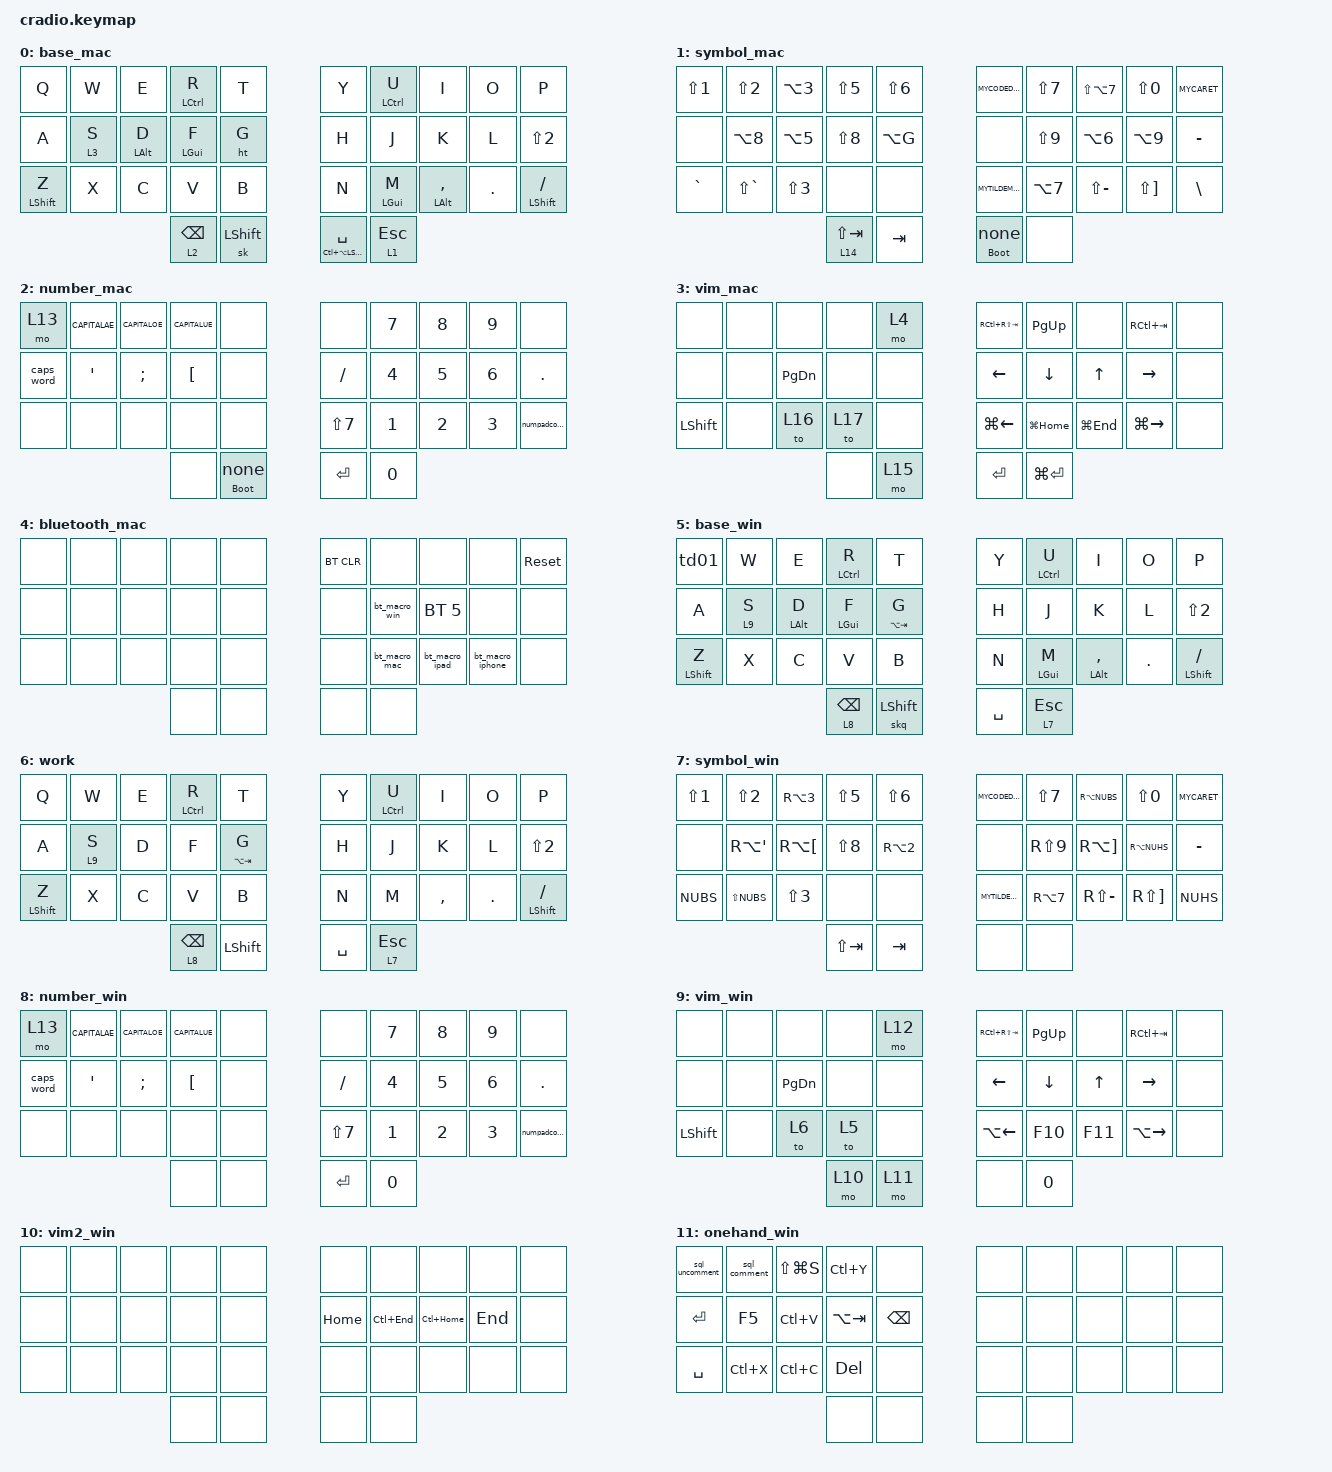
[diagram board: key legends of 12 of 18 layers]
// Copyright (c) 2022 The ZMK Contributors
// SPDX-License-Identifier: MIT

#include <behaviors.dtsi>
#include <dt-bindings/zmk/keys.h>
#include <dt-bindings/zmk/bt.h>

&sl {
    release-after-ms = <500>;
};

/ {
    behaviors {
        ht: hold_tap {
            label = "hold_tap";
            compatible = "zmk,behavior-hold-tap";
            #binding-cells = <2>;
            flavor = "balanced";
            tapping-term-ms = <150>;
            quick-tap-ms = <70>;
            global-quick-tap;
            bindings = <&kp>, <&kp>;
        };
        cht: custom_hold_tap {
            compatible = "zmk,behavior-hold-tap";
            label = "nested_ht_with_sk";
            #binding-cells = <2>;
            tapping-term-ms = <500>;
            flavor = "tap-preferred";
            bindings = <&mo>, <&skq>;
        };
        ht_reset: hold_tap_reset {
            label = "hold_tap_reset";
            compatible = "zmk,behavior-hold-tap";
            #binding-cells = <2>;
            flavor = "tap-preferred";
            tapping-term-ms = <3000>;
            quick-tap-ms = <150>;
            bindings = <&bootloader>, <&none>;
        };
      skq: sticky_key_quick_release {
           compatible = "zmk,behavior-sticky-key";
           label = "STICKY_KEY_QUICK_RELEASE";
           #binding-cells = <1>;
           bindings = <&kp>;
           release-after-ms = <700>;
           quick-release;
        };
// global quick tap to improve home row mod behavior ior when typing fast
      gqt: global-quick-tap {
           compatible = "zmk,behavior-hold-tap";
           label = "GLOBAL_QUICK_TAP";
           #binding-cells = <2>;
           flavor = "tap-preferred";
           tapping-term-ms = <200>;
           quick-tap-ms = <125>;
           global-quick-tap;
           bindings = <&kp>, <&kp>;
        };
//custom hold tap for layer tap - lqt
      lqt: layer-quick-tap {
           compatible = "zmk,behavior-hold-tap";
           label = "LAYER_QUICK_TAP";
           #binding-cells = <2>;
           flavor = "hold-preferred";
           tapping-term-ms = <200>;
           quick-tap-ms = <125>;
           bindings = <&mo>, <&kp>;
        };
// archived tapdances
//      lqt_td: layer-quick-tap-tap-dance {
//           compatible = "zmk,behavior-hold-tap";
//           label = "LAYER_QUICK_TAP_TAP_DANCE";
//           #binding-cells = <2>;
//           flavor = "hold-preferred";
//           tapping-term-ms = <125>;
//           quick-tap-ms = <50>;
//           bindings = <&mo>, <&td1>;
//        };
//      lqt_td2: layer-quick-tap-tap-dance2 {
//           compatible = "zmk,behavior-hold-tap";
//           label = "LAYER_QUICK_TAP_TAP_DANCE2";
//           #binding-cells = <2>;
//           flavor = "hold-preferred";
//           tapping-term-ms = <200>;
//           quick-tap-ms = <225>;
//           bindings = <&mo>, <&td2>;
//        };
//      td1: td1 {
//           compatible = "zmk,behavior-tap-dance";
//           label = "td_left_thumb_1";
//           #binding-cells = <0>;
//           tapping-term-ms = <40>; //max time between taps
//           bindings =
//           <&kp BSPC>, <&kp LA(BSPC)>;
//          };
    // tap_dance to have tab dance and q
      td01: td01 {
           compatible = "zmk,behavior-tap-dance";
           #binding-cells = <0>;
           tapping-term-ms = <150>;
           bindings =
           <&kp Q>, <&macro_alttab>;
          };
    };

//    combos {
//        compatible = "zmk,combos";
//        combo_esc {
//            timeout-ms = <50>;
//            key-positions = <0 1>;
//            bindings = <&kp LG(SPACE)>;
//           };
//    };

//    conditional_layers {
//        compatible = "zmk,conditional-layers";
//        bt_layer {
//            if-layers = <1 2>;
//            then-layer = <3>;
//        };
//    };

    macros {
        sql_comment: sql_comment {
            label = "sql_comment";
            compatible = "zmk,behavior-macro";
            #binding-cells = <0>;
            bindings
                = <&macro_press &kp LCTRL>
                , <&macro_tap &kp K>
                , <&macro_tap &kp C>
                , <&macro_release &kp LCTRL>
                , <&macro_tap &kp RIGHT>
                ;
        };
        sql_uncomment: sql_uncomment {
            label = "sql_uncomment";
            compatible = "zmk,behavior-macro";
            #binding-cells = <0>;
            bindings
                = <&macro_press &kp LCTRL>
                , <&macro_tap &kp K>
                , <&macro_tap &kp U>
                , <&macro_release &kp LCTRL>
                , <&macro_tap &kp RIGHT>
                ;
        };
        numpadcomma: numpadcomma {
            label = "numpadcomma";
            compatible = "zmk,behavior-macro";
            #binding-cells = <0>;
            bindings
                = <&macro_tap &kp COMMA>
                , <&macro_tap &kp SPACE>
                ;
        };
        CAPITALAE: CAPITALAE {
            label = "CAPITALAE";
            compatible = "zmk,behavior-macro";
            #binding-cells = <0>;
            bindings
                = <&macro_tap &kp CAPS>
                , <&macro_tap &kp SQT>
                , <&macro_tap &kp CAPS>
                ;
        };
        CAPITALOE: CAPITALOE {
            label = "CAPITALOE";
            compatible = "zmk,behavior-macro";
            #binding-cells = <0>;
            bindings
                = <&macro_tap &kp CAPS>
                , <&macro_tap &kp SEMI>
                , <&macro_tap &kp CAPS>
                ;
        };
        CAPITALUE: CAPITALUE {
            label = "CAPITALUE";
            compatible = "zmk,behavior-macro";
            #binding-cells = <0>;
            bindings
                = <&macro_tap &kp CAPS>
                , <&macro_tap &kp LBKT>
                , <&macro_tap &kp CAPS>
                ;
        };
        MYCARET: MYCARET {
            label = "MYCARET";
            compatible = "zmk,behavior-macro";
            #binding-cells = <0>;
            bindings
                = <&macro_tap &kp EQUAL>
                , <&macro_tap &kp SPACE>
                ;
        };
        MYTILDEMAC: MYTILDEMAC {
            label = "MYTILDEMAC";
            compatible = "zmk,behavior-macro";
            #binding-cells = <0>;
            bindings
                = <&macro_press &kp LALT>
                , <&macro_tap &kp N>
                , <&macro_release &kp LALT>
                , <&macro_tap &kp SPACE>
                ;
        };
        MYTILDEWIN: MYTILDEWIN {
            label = "MYTILDEWIN";
            compatible = "zmk,behavior-macro";
            #binding-cells = <0>;
            bindings
                = <&macro_press &kp RALT>
                , <&macro_tap &kp EQUAL>
                , <&macro_release &kp RALT>
                , <&macro_tap &kp SPACE>
                ;
        };
        MYCODEDELIM:  MYCODEDELIM {
            label = "MYCODEDELIM";
            compatible = "zmk,behavior-macro";
            #binding-cells = <0>;
            bindings
                = <&macro_tap &kp RS(EQUAL)>
                , <&macro_tap &kp SPACE>
                ;
        };
        bt_macro_mac: bt_macro_mac {
            label = "bt_macro_mac";
            compatible = "zmk,behavior-macro";
            #binding-cells = <0>;
            wait-ms = <0>;
            tap-ms = <0>;
            bindings = <&to 0>,  <&bt BT_SEL 1>;
        };
        bt_macro_win: bt_macro_win {
            label = "bt_macro_win";
            compatible = "zmk,behavior-macro";
            #binding-cells = <0>;
            wait-ms = <0>;
            tap-ms = <0>;
            bindings = <&to 5>,  <&bt BT_SEL 4>;
        };
        bt_macro_iphone: bt_macro_iphone {
            label = "bt_macro_iphone";
            compatible = "zmk,behavior-macro";
            #binding-cells = <0>;
            wait-ms = <0>;
            tap-ms = <0>;
            bindings = <&to 0>,  <&bt BT_SEL 3>;
        };
        bt_macro_ipad: bt_macro_ipad {
            label = "bt_macro_ipad";
            compatible = "zmk,behavior-macro";
            #binding-cells = <0>;
            wait-ms = <0>;
            tap-ms = <0>;
            bindings = <&to 0>,  <&bt BT_SEL 2>;
        };
        macro_alttab: macro_alttab {
            compatible = "zmk,behavior-macro";
            #binding-cells = <0>;
            bindings
                = <&macro_press &kp LALT>
                , <&macro_tap &kp TAB>
                , <&macro_pause_for_release>
                , <&macro_release &kp TAB>
                ;
        };
        app_switch: app_switch {
            compatible = "zmk,behavior-macro";
            #binding-cells = <0>;
            bindings
                = <&macro_press &kp LGUI>
                , <&macro_tap &kp TAB>
                , <&macro_pause_for_release>
                , <&macro_release &kp LGUI>;
        };
    };

// layernames will have the ending digit 1 if they are intended for use with MACOS
// layernames will have the ending digit 2 if they are intended for use with WINDOWS


    keymap {
        compatible = "zmk,keymap";

        // LAYER 0 base_mac
        base_mac {
            bindings = <
        //╭──────────┬──────────┬──────────┬──────────┬──────────╮   ╭──────────┬──────────┬──────────┬──────────┬──────────╮
        //│  Q       │  W       │  E       │  R       │  T       │   │  Z       │  U       │  I       │  O       │  P       │
            &kp Q      &kp W      &kp E     &ht LCTRL R &kp T          &kp Y    &ht LCTRL U   &kp I      &kp O      &kp P
        //├──────────┼──────────┼──────────┼──────────┼──────────┤   ├──────────┼──────────┼──────────┼──────────┼──────────┤
        //│  A       │  S       │  D       │  F       │  G       │   │  H       │  J       │  K       │  L       │  "       │
            &kp A      &lt 3 S    &ht LALT D   &ht LGUI F  &ht G      &kp H     &kp J       &kp K     &kp L     &kp LS(N2)
        //├──────────┼──────────┼──────────┼──────────┼──────────┤   ├──────────┼──────────┼──────────┼──────────┼──────────┤
        //│  Y       │  X       │  C       │  V       │  B       │   │  N       │  M       │ , <      │ . >      │ / ?      │
           &ht LSHIFT Z &kp X      &kp  C     &kp V      &kp B          &kp N     &ht LGUI M  &ht LALT COMMA &kp DOT &ht LSHIFT FSLH
        //╰──────────┴──────────┴──────────┼──────────┼──────────┤   ├──────────┼──────────┼──────────┴──────────┴──────────╯
                                            &lqt 2 BSPC &sk LSHIFT     &ht LC(LA(LSHIFT)) SPACE  &lqt 1 ESCAPE
        //                                 ╰──────────┴──────────╯   ╰──────────┴──────────╯
            >;
        };

// LAYER 1 symbol_mac
        symbol_mac {
            bindings = <
        //╭──────────┬──────────┬──────────┬──────────┬──────────╮   ╭──────────┬──────────┬──────────┬──────────┬──────────╮
        //│ +        │  "       │ \#       │  %       │    &     │   │   \`     │   /      │   \      │   =      │ caret    │
            &kp LS(N1) &kp LS(N2) &kp LA(N3) &kp LS(N5)  &kp LS(N6)    &MYCODEDELIM  &kp LS(N7)  &kp LS(LA(N7)) &kp LS(N0) &MYCARET
        //├──────────┼──────────┼──────────┼──────────┼──────────┤   ├──────────┼──────────┼──────────┼──────────┼──────────┤
        //│          │  {       │  [       │  (       │          │   │          │    )     │  ]       │     }    │  '       │
           &none   &kp LA(N8) &kp LA(N5) &kp LS(N8) &kp LA(G)        &none  &kp LS(N9) &kp LA(N6) &kp LA(N9) &kp MINUS
        //├──────────┼──────────┼──────────┼──────────┼──────────┤   ├──────────┼──────────┼──────────┼──────────┼──────────┤
        //│ <        │  >       │  *       │  9       │          │   │ tilde    │  pipe    │  ?       │     !    │  $       │
           &kp GRAVE   &kp LS(GRAVE) &kp LS(N3) &none    &none      &MYTILDEMAC    &kp LA(N7)   &kp LS(MINUS) &kp LS(RBKT) &kp BSLH
        //╰──────────┴──────────┴──────────┼──────────┼──────────┤   ├──────────┼──────────┼──────────┴──────────┴──────────╯
                                             &lt 14 LS(TAB) &kp TAB   &ht_reset 0 0  &none
        //                                 ╰──────────┴──────────╯   ╰──────────┴──────────╯
            >;
        };

// LAYER 2 number_mac
        number_mac {
            bindings = <
        //╭──────────┬──────────┬──────────┬──────────┬──────────╮   ╭──────────┬──────────┬──────────┬──────────┬──────────╮
        //│          │          │          │          │          │   │          │  7       │  8       │  9       │          │
            &mo 13      &CAPITALAE     &CAPITALOE      &CAPITALUE      &none          &none      &kp N7     &kp N8     &kp N9   &none
        //├──────────┼──────────┼──────────┼──────────┼──────────┤   ├──────────┼──────────┼──────────┼──────────┼──────────┤
        //│          │ ä        │   ö      │   ü      │          │   │     -    │  4       │  5       │  6       │          │
           &caps_word      &kp SQT     &kp SEMI     &kp LBKT  &none    &kp FSLH &kp N4     &kp N5     &kp N6     &kp DOT
        //├──────────┼──────────┼──────────┼──────────┼──────────┤   ├──────────┼──────────┼──────────┼──────────┼──────────┤
        //│          │          │          │          │          │   │     /    │  1       │   2      │    3     │          │
            &none      &none      &none      &none       &none         &kp LS(N7)     &kp N1    &kp N2     &kp N3     &numpadcomma
        //╰──────────┴──────────┴──────────┼──────────┼──────────┤   ├──────────┼──────────┼──────────┴──────────┴──────────╯
                                             &none  &ht_reset 0 0  &kp ENTER   &kp N0
        //                                 ╰──────────┴──────────╯   ╰──────────┴──────────╯
            >;
        };

// LAYER 3 vim_mac
        vim_mac {
            bindings = <
        //╭──────────┬──────────┬──────────┬──────────┬──────────╮   ╭──────────┬──────────┬──────────┬──────────┬──────────╮
        //│          │          │          │          │          │   │          │          │          │          │          │
            &none      &none     &none      &none      &mo 4           &kp RC(RS(TAB))      &kp PG_UP     &none   &kp RC(TAB)   &none
        //├──────────┼──────────┼──────────┼──────────┼──────────┤   ├──────────┼──────────┼──────────┼──────────┼──────────┤
        //│          │          │          │          │          │   │          │          │          │          │          │
           &none      &none      &kp PG_DN     &none       &none         &kp LEFT    &kp DOWN   &kp UP    &kp RIGHT  &none
        //├──────────┼──────────┼──────────┼──────────┼──────────┤   ├──────────┼──────────┼──────────┼──────────┼──────────┤
        //│          │          │          │          │          │   │          │          │          │          │          │
            &kp LSHIFT   &none     &to 16     &to 17      &none       &kp LG(LEFT) &kp LG(HOME) &kp LG(END) &kp LG(RIGHT)  &none
        //╰──────────┴──────────┴──────────┼──────────┼──────────┤   ├──────────┼──────────┼──────────┴──────────┴──────────╯
                                             &none      &mo 15          &kp ENTER      &kp LG(ENTER)
        //                                 ╰──────────┴──────────╯   ╰──────────┴──────────╯
            >;
        };

// LAYER 4 bluetooth_mac
        bluetooth_mac {
            bindings = <
        //╭──────────┬──────────┬──────────┬──────────┬──────────╮   ╭──────────┬──────────┬──────────┬──────────┬──────────╮
        //│          │          │          │          │          │   │ CLEAR BT │          │          │          │          │
            &none     &none      &none      &none     &none          &bt BT_CLR &none      &none      &none       &sys_reset
        //├──────────┼──────────┼──────────┼──────────┼──────────┤   ├──────────┼──────────┼──────────┼──────────┼──────────┤
        //│          │          │          │          │          │   │          │Profile 4 │Profile 5 │          │          │
          &none  &none      &none      &none     &none           &none   &bt_macro_win &bt BT_SEL 5 &none     &none
        //├──────────┼──────────┼──────────┼──────────┼──────────┤   ├──────────┼──────────┼──────────┼──────────┼──────────┤
        //│          │          │          │          │          │   │          │Profile 1 │Profile 2 │Profile 3 │          │
            &none      &none      &none     &none        &none         &none     &bt_macro_mac &bt_macro_ipad &bt_macro_iphone &none
        //╰──────────┴──────────┴──────────┼──────────┼──────────┤   ├──────────┼──────────┼──────────┴──────────┴──────────╯
                                             &none      &none          &none      &none
        //                                 ╰──────────┴──────────╯   ╰──────────┴──────────╯
            >;
        };

//// LAYER 4 bluetooth_layer1 (uncommented no macros)
//        bluetooth_layer1 {
//            bindings = <
//        //╭──────────┬──────────┬──────────┬──────────┬──────────╮   ╭──────────┬──────────┬──────────┬──────────┬──────────╮
//        //│          │          │          │          │          │   │ CLEAR BT │          │          │          │          │
//            &none     &none      &none      &none     &none          &bt BT_CLR &none      &none      &none       &sys_reset
//        //├──────────┼──────────┼──────────┼──────────┼──────────┤   ├──────────┼──────────┼──────────┼──────────┼──────────┤
//        //│          │          │          │          │          │   │          │Profile 4 │Profile 5 │          │          │
//          &none  &none      &none      &none     &none           &none   &bt BT_SEL 4 &bt BT_SEL 5 &none     &none
//        //├──────────┼──────────┼──────────┼──────────┼──────────┤   ├──────────┼──────────┼──────────┼──────────┼──────────┤
//        //│          │          │          │          │          │   │          │Profile 1 │Profile 2 │Profile 3 │          │
//            &none      &none      &none     &none        &none         &none     &bt BT_SEL 1 &bt BT_SEL 2 &bt BT_SEL 3 &none
//        //╰──────────┴──────────┴──────────┼──────────┼──────────┤   ├──────────┼──────────┼──────────┴──────────┴──────────╯
//                                             &none      &none          &to 0      &to 5
//        //                                 ╰──────────┴──────────╯   ╰──────────┴──────────╯
//            >;
//        };

// LAYER 5 base_win
        base_win {
            bindings = <
        //╭──────────┬──────────┬──────────┬──────────┬──────────╮   ╭──────────┬──────────┬──────────┬──────────┬──────────╮
        //│  Q       │  W       │  E       │  R       │  T       │   │  Z       │  U       │  I       │  O       │  P       │
            &td01      &kp W      &kp E     &ht LCTRL R &kp T          &kp Y      &ht LCTRL U      &kp I      &kp O      &kp P
        //├──────────┼──────────┼──────────┼──────────┼──────────┤   ├──────────┼──────────┼──────────┼──────────┼──────────┤
        //│  A       │  S       │  D       │  F       │  G       │   │  H       │  J       │  K       │  L       │  "      │
            &kp A      &lt 9 S    &ht LALT D  &ht LGUI F    &ht LA(TAB) G   &kp H      &kp J       &kp K     &kp L      &kp LS(N2)
        //├──────────┼──────────┼──────────┼──────────┼──────────┤   ├──────────┼──────────┼──────────┼──────────┼──────────┤
        //│  Y       │  X       │  C       │  V       │  B       │   │  N       │  M       │ , <      │ . >      │ / ?      │
           &ht LSHIFT Z &kp X      &kp  C     &kp V     &kp B          &kp N     &ht LGUI M  &ht LALT COMMA &kp DOT &ht LSHIFT FSLH
        //╰──────────┴──────────┴──────────┼──────────┼──────────┤   ├──────────┼──────────┼──────────┴──────────┴──────────╯
                                            &lqt 8 BSPC &skq LSHIFT     &kp SPACE  &lqt 7 ESCAPE
        //                                 ╰──────────┴──────────╯   ╰──────────┴──────────╯
            >;
        };

// LAYER 6 work - not sure whether needed
        work {
            bindings = <
        //╭──────────┬──────────┬──────────┬──────────┬──────────╮   ╭──────────┬──────────┬──────────┬──────────┬──────────╮
        //│  Q       │  W       │  E       │  R       │  T       │   │  Z       │  U       │  I       │  O       │  P       │
            &kp Q      &kp W      &kp E     &ht LCTRL R &kp T          &kp Y      &ht LCTRL U      &kp I      &kp O      &kp P
        //├──────────┼──────────┼──────────┼──────────┼──────────┤   ├──────────┼──────────┼──────────┼──────────┼──────────┤
        //│  A       │  S       │  D       │  F       │  G       │   │  H       │  J       │  K       │  L       │  "       │
            &kp A      &lt 9 S    &kp D     &kp F    &ht LA(TAB) G     &kp H      &kp J      &kp K      &kp L     &kp LS(N2)
        //├──────────┼──────────┼──────────┼──────────┼──────────┤   ├──────────┼──────────┼──────────┼──────────┼──────────┤
        //│  Y       │  X       │  C       │  V       │  B       │   │  N       │  M       │ , <      │ . >      │ / ?      │
           &ht LSHIFT Z &kp X    &kp C       &kp V       &kp B          &kp N     &kp  M  &kp COMMA &kp DOT &ht LSHIFT FSLH
        //╰──────────┴──────────┴──────────┼──────────┼──────────┤   ├──────────┼──────────┼──────────┴──────────┴──────────╯
                                            &lqt 8 BSPC &kp LSHIFT     &kp SPACE  &lqt 7 ESCAPE
        //                                 ╰──────────┴──────────╯   ╰──────────┴──────────╯
            >;
        };

// LAYER 7 symbol_win
        symbol_win {
            bindings = <
        //╭──────────┬──────────┬──────────┬──────────┬──────────╮   ╭──────────┬──────────┬──────────┬──────────┬──────────╮
        //│ +        │  "       │ \#       │  %       │    &     │   │   \`     │   /      │   \      │   =      │ caret    │
            &kp LS(N1) &kp LS(N2) &kp RA(N3) &kp LS(N5)  &kp LS(N6)    &MYCODEDELIM  &kp LS(N7)  &kp RA(NUBS) &kp LS(N0) &MYCARET
        //├──────────┼──────────┼──────────┼──────────┼──────────┤   ├──────────┼──────────┼──────────┼──────────┼──────────┤
        //│          │  {       │  [       │  (       │          │   │          │    )     │  ]       │     }    │  '       │
           &none   &kp RA(SQT) &kp RA(LBKT) &kp LS(N8) &kp RA(N2)        &none  &kp RS(N9) &kp RA(RBKT) &kp RA(NUHS) &kp MINUS
        //├──────────┼──────────┼──────────┼──────────┼──────────┤   ├──────────┼──────────┼──────────┼──────────┼──────────┤
        //│ <        │  >       │  *       │  9       │  0       │   │ tilde    │  pipe    │  ?       │     !    │  $       │
           &kp NUBS   &kp LS(NUBS) &kp LS(N3) &none   &none         &MYTILDEWIN      &kp RA(N7)   &kp RS(MINUS) &kp RS(RBKT) &kp NUHS
        //╰──────────┴──────────┴──────────┼──────────┼──────────┤   ├──────────┼──────────┼──────────┴──────────┴──────────╯
                                             &kp LS(TAB) &kp TAB        &none      &none
        //                                 ╰──────────┴──────────╯   ╰──────────┴──────────╯
            >;
        };

// LAYER 8 number_win
        number_win {
            bindings = <
        //╭──────────┬──────────┬──────────┬──────────┬──────────╮   ╭──────────┬──────────┬──────────┬──────────┬──────────╮
        //│          │          │          │          │          │   │          │  7       │  8       │  9       │          │
            &mo 13      &CAPITALAE     &CAPITALOE      &CAPITALUE      &none          &none      &kp N7     &kp N8     &kp N9   &none
        //├──────────┼──────────┼──────────┼──────────┼──────────┤   ├──────────┼──────────┼──────────┼──────────┼──────────┤
        //│          │ ä        │   ö      │   ü      │          │   │    -     │  4       │  5       │  6       │          │
           &caps_word      &kp SQT     &kp SEMI     &kp LBKT  &none     &kp FSLH  &kp N4     &kp N5     &kp N6     &kp DOT
        //├──────────┼──────────┼──────────┼──────────┼──────────┤   ├──────────┼──────────┼──────────┼──────────┼──────────┤
        //│          │          │          │          │          │   │    /     │  1       │   2      │    3     │          │
            &none      &none      &none      &none      &none          &kp LS(N7)     &kp N1    &kp N2     &kp N3     &numpadcomma
        //╰──────────┴──────────┴──────────┼──────────┼──────────┤   ├──────────┼──────────┼──────────┴──────────┴──────────╯
                                             &none      &none          &kp ENTER      &kp N0
        //                                 ╰──────────┴──────────╯   ╰──────────┴──────────╯
            >;
        };

// LAYER 9 vim_win
        vim_win {
            bindings = <
        //╭──────────┬──────────┬──────────┬──────────┬──────────╮   ╭──────────┬──────────┬──────────┬──────────┬──────────╮
        //│          │          │          │          │          │   │          │          │          │          │         │
            &none      &none     &none      &none      &mo 12           &kp RC(RS(TAB))      &kp PG_UP     &none   &kp RC(TAB)   &none
        //├──────────┼──────────┼──────────┼──────────┼──────────┤   ├──────────┼──────────┼──────────┼──────────┼──────────┤
        //│          │          │          │          │          │   │          │          │          │          │          │
           &none      &none      &kp PG_DN     &none       &none         &kp LEFT    &kp DOWN   &kp UP    &kp RIGHT  &none
        //├──────────┼──────────┼──────────┼──────────┼──────────┤   ├──────────┼──────────┼──────────┼──────────┼──────────┤
        //│          │          │          │          │          │   │          │          │          │          │          │
            &kp LSHIFT   &none      &to 6      &to 5      &none       &kp LA(LEFT) &kp F10    &kp F11     &kp LA(RIGHT)  &none
        //╰──────────┴──────────┴──────────┼──────────┼──────────┤   ├──────────┼──────────┼──────────┴──────────┴──────────╯
                                             &mo 10      &mo 11          &none      &kp N0
        //                                 ╰──────────┴──────────╯   ╰──────────┴──────────╯
            >;
        };

// LAYER 10 vim2_win
        vim2_win {
            bindings = <
        //╭──────────┬──────────┬──────────┬──────────┬──────────╮   ╭──────────┬──────────┬──────────┬──────────┬──────────╮
        //│          │          │          │          │          │   │          │          │          │          │          │
            &none      &none     &none      &none      &none           &none      &none     &none   &none   &none
        //├──────────┼──────────┼──────────┼──────────┼──────────┤   ├──────────┼──────────┼──────────┼──────────┼──────────┤
        //│          │          │          │          │          │   │          │          │          │          │          │
           &none      &none      &none     &none       &none         &kp HOME    &kp LC(END)   &kp LC(HOME)    &kp END  &none
        //├──────────┼──────────┼──────────┼──────────┼──────────┤   ├──────────┼──────────┼──────────┼──────────┼──────────┤
        //│          │          │          │          │          │   │          │          │          │          │          │
            &none      &none      &none      &none      &none          &none      &none    &none     &none     &none
        //╰──────────┴──────────┴──────────┼──────────┼──────────┤   ├──────────┼──────────┼──────────┴──────────┴──────────╯
                                             &none      &none          &none      &none
        //                                 ╰──────────┴──────────╯   ╰──────────┴──────────╯
            >;
        };

 // LAYER 11 onehand_win
        onehand_win {
            bindings = <
        //╭──────────┬──────────┬──────────┬──────────┬──────────╮   ╭──────────┬──────────┬──────────┬──────────┬──────────╮
        //│          │          │          │          │          │   │          │          │          │          │          │
            &sql_uncomment     &sql_comment &kp LS(LG(S))      &kp LC(Y)      &none           &none      &none     &none     &none   &none
        //├──────────┼──────────┼──────────┼──────────┼──────────┤   ├──────────┼──────────┼──────────┼──────────┼──────────┤
        //│          │          │          │          │          │   │          │          │          │          │          │
           &kp ENTER      &kp F5      &kp LC(V) &kp LA(TAB)  &kp BSPC         &none    &none   &none    &none  &none
        //├──────────┼──────────┼──────────┼──────────┼──────────┤   ├──────────┼──────────┼──────────┼──────────┼──────────┤
        //│          │          │          │          │          │   │          │          │          │          │          │
            &kp SPACE      &kp LC(X)      &kp LC(C)      &kp DEL      &none          &none      &none    &none     &none     &none
        //╰──────────┴──────────┴──────────┼──────────┼──────────┤   ├──────────┼──────────┼──────────┴──────────┴──────────╯
                                             &none      &none          &none      &none
        //                                 ╰──────────┴──────────╯   ╰──────────┴──────────╯
            >;
        };

// LAYER 12 bluetooth_win
        bluetooth_win {
            bindings = <
        //╭──────────┬──────────┬──────────┬──────────┬──────────╮   ╭──────────┬──────────┬──────────┬──────────┬──────────╮
        //│          │          │          │          │          │   │ CLEAR BT │          │          │          │          │
            &none     &none      &none      &none     &none          &bt BT_CLR &none      &none      &none       &sys_reset
        //├──────────┼──────────┼──────────┼──────────┼──────────┤   ├──────────┼──────────┼──────────┼──────────┼──────────┤
        //│          │          │          │          │          │   │          │Profile 4 │Profile 5 │          │          │
          &none  &none      &none      &none     &none           &none   &bt_macro_win &bt BT_SEL 5 &none     &none
        //├──────────┼──────────┼──────────┼──────────┼──────────┤   ├──────────┼──────────┼──────────┼──────────┼──────────┤
        //│          │          │          │          │          │   │          │Profile 1 │Profile 2 │Profile 3 │          │
            &none      &none      &none     &none        &none         &none     &bt_macro_mac &bt_macro_ipad &bt_macro_iphone &none
        //╰──────────┴──────────┴──────────┼──────────┼──────────┤   ├──────────┼──────────┼──────────┴──────────┴──────────╯
                                             &none      &none          &none      &none
        //                                 ╰──────────┴──────────╯   ╰──────────┴──────────╯
            >;
        };

//// LAYER 12 bluetooth_win (no macro version)
//        bluetooth_win {
//            bindings = <
//        //╭──────────┬──────────┬──────────┬──────────┬──────────╮   ╭──────────┬──────────┬──────────┬──────────┬──────────╮
//        //│          │          │          │          │          │   │ CLEAR BT │          │          │          │          │
//            &none     &none      &none      &none     &none          &bt BT_CLR &none      &none      &none       &none
//        //├──────────┼──────────┼──────────┼──────────┼──────────┤   ├──────────┼──────────┼──────────┼──────────┼──────────┤
//        //│          │          │          │          │          │   │          │Profile 4 │Profile 5 │          │          │
//          &none  &none      &none      &none     &none           &none   &bt BT_SEL 4 &bt BT_SEL 5 &none     &none
//        //├──────────┼──────────┼──────────┼──────────┼──────────┤   ├──────────┼──────────┼──────────┼──────────┼──────────┤
//        //│          │          │          │          │          │   │          │Profile 1 │Profile 2 │Profile 3 │          │
//            &none      &none      &none     &none        &none         &none     &bt BT_SEL 1 &bt BT_SEL 2 &bt BT_SEL 3 &none
//        //╰──────────┴──────────┴──────────┼──────────┼──────────┤   ├──────────┼──────────┼──────────┴──────────┴──────────╯
//                                             &none      &none          &to 0      &to 5
//        //                                 ╰──────────┴──────────╯   ╰──────────┴──────────╯
//            >;
//        };

// LAYER 13 fn_layer
        fn_layer {
            bindings = <
        //╭──────────┬──────────┬──────────┬──────────┬──────────╮   ╭──────────┬──────────┬──────────┬──────────┬──────────╮
        //│          │          │          │          │          │   │          │          │          │          │          │
            &none     &none      &none      &none      &none           &kp F12      &kp F7      &kp F8      &kp F9      &none
        //├──────────┼──────────┼──────────┼──────────┼──────────┤   ├──────────┼──────────┼──────────┼──────────┼──────────┤
        //│          │          │          │          │          │   │          │          │          │          │          │
            &none     &none      &none      &none      &none           &kp F11      &kp F4      &kp F5      &kp F6      &none
        //├──────────┼──────────┼──────────┼──────────┼──────────┤   ├──────────┼──────────┼──────────┼──────────┼──────────┤
        //│          │          │          │          │          │   │          │          │          │          │          │
            &none     &none      &none      &none      &none           &kp F10      &kp F1      &kp F2       &kp F3      &none
        //╰──────────┴──────────┴──────────┼──────────┼──────────┤   ├──────────┼──────────┼──────────┴──────────┴──────────╯
                                             &none &kp TAB        &none      &none
        //                                 ╰──────────┴──────────╯   ╰──────────┴──────────╯
            >;
        };

// LAYER 14 media_layer
        media_layer {
            bindings = <
        //╭──────────┬──────────┬──────────┬──────────┬──────────╮   ╭──────────┬──────────┬──────────┬──────────┬──────────╮
        //│          │          │          │          │          │   │          │          │          │          │          │
            &kp C_BRI_DN &kp C_BRI_UP  &kp LG(LS(N3))  &none &none     &none      &kp K_VOL_DN      &kp K_MUTE      &kp K_VOL_UP      &none
        //├──────────┼──────────┼──────────┼──────────┼──────────┤   ├──────────┼──────────┼──────────┼──────────┼──────────┤
        //│          │          │          │          │          │   │          │          │          │          │          │
            &none     &none      &none      &none      &none           &none      &kp C_PREV      &kp C_PP      &kp C_NEXT      &none
        //├──────────┼──────────┼──────────┼──────────┼──────────┤   ├──────────┼──────────┼──────────┼──────────┼──────────┤
        //│          │          │          │          │          │   │          │          │          │          │          │
//                                                                              lights less bright  │  lights brighter       in hue in the menu
            &none     &none      &none      &none      &none           &none    &kp LG(LC(LS(H)))     &none &kp LG(LC(LS(Y)))       &none
        //╰──────────┴──────────┴──────────┼──────────┼──────────┤   ├──────────┼──────────┼──────────┴──────────┴──────────╯
                                             &none &kp TAB        &none      &none
        //                                 ╰──────────┴──────────╯   ╰──────────┴──────────╯
            >;
        };

// LAYER 15 onehand_mac (mac)
        onehand_mac {
            bindings = <
        //╭──────────┬──────────┬──────────┬──────────┬──────────╮   ╭──────────┬──────────┬──────────┬──────────┬──────────╮
        //│          │          │          │          │          │   │          │          │          │          │          │
            &none     &none &kp LG(LC(LS(N4))) &kp LG(Y) &none           &none      &none     &none     &none   &none
        //├──────────┼──────────┼──────────┼──────────┼──────────┤   ├──────────┼──────────┼──────────┼──────────┼──────────┤
        //│          │          │          │          │          │   │          │          │          │          │          │
           &kp ENTER      &none      &kp LG(V) &app_switch  &kp BSPC         &none    &none   &none    &none  &none
        //├──────────┼──────────┼──────────┼──────────┼──────────┤   ├──────────┼──────────┼──────────┼──────────┼──────────┤
        //│          │          │          │          │          │   │          │          │          │          │          │
            &kp SPACE      &kp LG(X)      &kp LG(C)      &kp DEL      &none          &none      &none    &none     &none     &none
        //╰──────────┴──────────┴──────────┼──────────┼──────────┤   ├──────────┼──────────┼──────────┴──────────┴──────────╯
                                             &none      &none          &none      &none
        //                                 ╰──────────┴──────────╯   ╰──────────┴──────────╯
            >;
        };

// LAYER 16 add_layerA (arrow_keys on ESDF)
// additional layer for one handed keyboard use
// done for navigating slides or books with left hand and writing with right hand
        add_layerA {
            bindings = <
        //╭──────────┬──────────┬──────────┬──────────┬──────────╮   ╭──────────┬──────────┬──────────┬──────────┬──────────╮
        //│          │          │          │          │          │   │          │          │          │          │          │
            &none      &none     &kp UP      &none      &none           &none      &none     &none   &none   &to 0
        //├──────────┼──────────┼──────────┼──────────┼──────────┤   ├──────────┼──────────┼──────────┼──────────┼──────────┤
        //│          │          │          │          │          │   │          │          │          │          │          │
           &none      &kp LEFT      &kp DOWN     &kp RIGHT       &none         &none    &none   &none    &none  &none
        //├──────────┼──────────┼──────────┼──────────┼──────────┤   ├──────────┼──────────┼──────────┼──────────┼──────────┤
        //│          │          │          │          │          │   │          │          │          │          │          │
            &none      &none      &none      &none      &none          &none      &none    &none     &none     &none
        //╰──────────┴──────────┴──────────┼──────────┼──────────┤   ├──────────┼──────────┼──────────┴──────────┴──────────╯
                                             &none      &none          &none      &none
        //                                 ╰──────────┴──────────╯   ╰──────────┴──────────╯
            >;
        };

// LAYER 17 add_layerB (layer for anki)
// additional layer for one handed keyboard use
// to use with anki
        add_layerB {
            bindings = <
        //╭──────────┬──────────┬──────────┬──────────┬──────────╮   ╭──────────┬──────────┬──────────┬──────────┬──────────╮
        //│          │          │          │          │          │   │          │          │          │          │          │
            &none      &none     &kp UP      &none      &none           &none      &none     &none   &none   &to 0
        //├──────────┼──────────┼──────────┼──────────┼──────────┤   ├──────────┼──────────┼──────────┼──────────┼──────────┤
        //│          │          │          │          │          │   │          │  flag    │ flag     │          │          │
           &kp N1      &kp N2      &kp N3     &kp N4       &kp U         &none    &kp LG(N4)   &none    &none  &none
        //├──────────┼──────────┼──────────┼──────────┼──────────┤   ├──────────┼──────────┼──────────┼──────────┼──────────┤
        //│          │          │          │ =   bury │ @ suspend│   │          │  flag    │   flag   │  flag    │          │
            &none      &none      &none      &kp LS(LA(N7))    &kp LA(G)   &none    &kp LG(N1)    &kp LG(N2)     &kp LG(N3)     &none
        //╰──────────┴──────────┴──────────┼──────────┼──────────┤   ├──────────┼──────────┼──────────┴──────────┴──────────╯
                                             &none      &kp SPACE          &none      &none
        //                                 ╰──────────┴──────────╯   ╰──────────┴──────────╯
            >;
        };

    };
};
